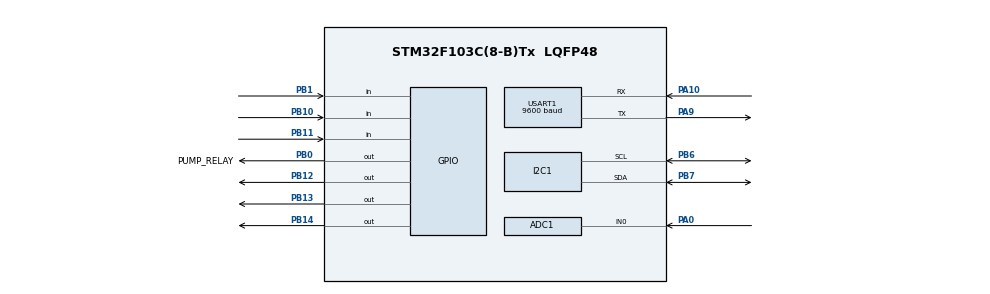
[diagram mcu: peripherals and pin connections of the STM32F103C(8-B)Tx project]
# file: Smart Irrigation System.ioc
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ADC1.Channel-0\#ChannelRegularConversion=ADC_CHANNEL_0
ADC1.NbrOfConversionFlag=1
ADC1.Rank-0\#ChannelRegularConversion=1
ADC1.SamplingTime-0\#ChannelRegularConversion=ADC_SAMPLETIME_1CYCLE_5
ADC1.master=1
FREERTOS.Events01=SoilEvent,Dynamic,NULL
FREERTOS.Mutexes01=UartMutex,Dynamic,NULL,Available;I2cMutex,Dynamic,NULL,Available
FREERTOS.Queues01=SoilAdcQueue,5,SoilData_t,0,Dynamic,NULL,NULL;SystemStatusQueue,5,SystemStatus_t,0,Dynamic,NULL,NULL;OledStatusQueue,3,SystemStatus_t,0,Dynamic,NULL,NULL
FREERTOS.Tasks01=SoilSensorTask,24,128,StartSoilSensorTask,Default,NULL,Dynamic,NULL,NULL;UartPrintTask,8,256,StartUartPrintTask,Default,NULL,Dynamic,NULL,NULL;PumpControlTask,32,512,StartPumpControlTask,Default,NULL,Dynamic,NULL,NULL;ButtonTask,24,128,StartButtonTask,Default,NULL,Dynamic,NULL,NULL;WaterTankTask,24,128,StartWaterTankTask,Default,NULL,Dynamic,NULL,NULL;SystemMonitorTa,8,128,StartSystemMonitorTask,Default,NULL,Dynamic,NULL,NULL;SystemStatusTas,8,256,StartSystemStatusTask,Default,NULL,Dynamic,NULL,NULL;OledDisplayTask,8,512,StartOledDisplayTask,Default,NULL,Dynamic,NULL,NULL
FREERTOS.configTOTAL_HEAP_SIZE=10000
FREERTOS.configUSE_NEWLIB_REENTRANT=1
Mcu.Family=STM32F1
Mcu.Name=STM32F103C(8-B)Tx
Mcu.Package=LQFP48
NVIC.PriorityGroup=NVIC_PRIORITYGROUP_4
NVIC.TIM2_IRQn=true\:15\:0\:false\:false\:true\:false\:false\:true\:true
NVIC.TimeBase=TIM2_IRQn
NVIC.TimeBaseIP=TIM2
PA0-WKUP.Signal=ADCx_IN0
PA10.Mode=Asynchronous
PA10.Signal=USART1_RX
PA13.Mode=Serial_Wire
PA13.Signal=SYS_JTMS-SWDIO
PA14.Mode=Serial_Wire
PA14.Signal=SYS_JTCK-SWCLK
PA9.Mode=Asynchronous
PA9.Signal=USART1_TX
PB0.GPIO_Label=PUMP_RELAY
PB0.Signal=GPIO_Output
PB1.GPIO_PuPd=GPIO_PULLUP
PB1.Signal=GPIO_Input
PB10.GPIO_PuPd=GPIO_PULLUP
PB10.Signal=GPIO_Input
PB11.GPIO_PuPd=GPIO_PULLUP
PB11.Signal=GPIO_Input
PB12.Signal=GPIO_Output
PB13.Signal=GPIO_Output
PB14.Signal=GPIO_Output
PB6.Mode=I2C
PB6.Signal=I2C1_SCL
PB7.Mode=I2C
PB7.Signal=I2C1_SDA
ProjectManager.HeapSize=0x200
ProjectManager.StackSize=0x400
ProjectManager.TargetToolchain=STM32CubeIDE
RCC.APB1Freq_Value=8000000
RCC.APB2Freq_Value=8000000
SH.ADCx_IN0.0=ADC1_IN0,IN0
USART1.BaudRate=9600
USART1.VirtualMode=VM_ASYNC
VP_FREERTOS_VS_CMSIS_V2.Mode=CMSIS_V2
VP_SYS_VS_tim2.Mode=TIM2
board=custom

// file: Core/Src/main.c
/* USER CODE BEGIN Header */
/**
  ******************************************************************************
  * @file           : main.c
  * @brief          : Main program body
  ******************************************************************************
  * @attention
  *
  * Copyright (c) 2026 STMicroelectronics.
  * All rights reserved.
  *
  * This software is licensed under terms that can be found in the LICENSE file
  * in the root directory of this software component.
  * If no LICENSE file comes with this software, it is provided AS-IS.
  *
  ******************************************************************************
  */
/* USER CODE END Header */
#include "main.h"
#include "cmsis_os.h"

/* USER CODE BEGIN Includes */
#include "APP.h"

/* USER CODE END Includes */

ADC_HandleTypeDef hadc1;

I2C_HandleTypeDef hi2c1;

UART_HandleTypeDef huart1;

/* Definitions for SoilSensorTask */
osThreadId_t SoilSensorTaskHandle;
const osThreadAttr_t SoilSensorTask_attributes = {
  .name = "SoilSensorTask",
  .stack_size = 128 * 4,
  .priority = (osPriority_t) osPriorityNormal,
};
/* Definitions for UartPrintTask */
osThreadId_t UartPrintTaskHandle;
const osThreadAttr_t UartPrintTask_attributes = {
  .name = "UartPrintTask",
  .stack_size = 256 * 4,
  .priority = (osPriority_t) osPriorityLow,
};
/* Definitions for PumpControlTask */
osThreadId_t PumpControlTaskHandle;
const osThreadAttr_t PumpControlTask_attributes = {
  .name = "PumpControlTask",
  .stack_size = 512 * 4,
  .priority = (osPriority_t) osPriorityAboveNormal,
};
/* Definitions for ButtonTask */
osThreadId_t ButtonTaskHandle;
const osThreadAttr_t ButtonTask_attributes = {
  .name = "ButtonTask",
  .stack_size = 128 * 4,
  .priority = (osPriority_t) osPriorityNormal,
};
/* Definitions for WaterTankTask */
osThreadId_t WaterTankTaskHandle;
const osThreadAttr_t WaterTankTask_attributes = {
  .name = "WaterTankTask",
  .stack_size = 128 * 4,
  .priority = (osPriority_t) osPriorityNormal,
};
/* Definitions for SystemMonitorTa */
osThreadId_t SystemMonitorTaHandle;
const osThreadAttr_t SystemMonitorTa_attributes = {
  .name = "SystemMonitorTa",
  .stack_size = 128 * 4,
  .priority = (osPriority_t) osPriorityLow,
};
/* Definitions for SystemStatusTas */
osThreadId_t SystemStatusTasHandle;
const osThreadAttr_t SystemStatusTas_attributes = {
  .name = "SystemStatusTas",
  .stack_size = 256 * 4,
  .priority = (osPriority_t) osPriorityLow,
};
/* Definitions for OledDisplayTask */
osThreadId_t OledDisplayTaskHandle;
const osThreadAttr_t OledDisplayTask_attributes = {
  .name = "OledDisplayTask",
  .stack_size = 512 * 4,
  .priority = (osPriority_t) osPriorityLow,
};
/* Definitions for SoilAdcQueue */
osMessageQueueId_t SoilAdcQueueHandle;
const osMessageQueueAttr_t SoilAdcQueue_attributes = {
  .name = "SoilAdcQueue"
};
/* Definitions for SystemStatusQueue */
osMessageQueueId_t SystemStatusQueueHandle;
const osMessageQueueAttr_t SystemStatusQueue_attributes = {
  .name = "SystemStatusQueue"
};
/* Definitions for OledStatusQueue */
osMessageQueueId_t OledStatusQueueHandle;
const osMessageQueueAttr_t OledStatusQueue_attributes = {
  .name = "OledStatusQueue"
};
/* Definitions for UartMutex */
osMutexId_t UartMutexHandle;
const osMutexAttr_t UartMutex_attributes = {
  .name = "UartMutex"
};
/* Definitions for I2cMutex */
osMutexId_t I2cMutexHandle;
const osMutexAttr_t I2cMutex_attributes = {
  .name = "I2cMutex"
};
/* Definitions for SoilEvent */
osEventFlagsId_t SoilEventHandle;
const osEventFlagsAttr_t SoilEvent_attributes = {
  .name = "SoilEvent"
};

void SystemClock_Config(void);
static void MX_GPIO_Init(void);
static void MX_ADC1_Init(void);
static void MX_USART1_UART_Init(void);
static void MX_I2C1_Init(void);
void StartSoilSensorTask(void *argument);
void StartUartPrintTask(void *argument);
void StartPumpControlTask(void *argument);
void StartButtonTask(void *argument);
void StartWaterTankTask(void *argument);
void StartSystemMonitorTask(void *argument);
void StartSystemStatusTask(void *argument);
void StartOledDisplayTask(void *argument);

int main(void)
{

  /* MCU Configuration--------------------------------------------------------*/

  /* Reset of all peripherals, Initializes the Flash interface and the Systick. */
  HAL_Init();

  /* Configure the system clock */
  SystemClock_Config();

  /* Initialize all configured peripherals */
  MX_GPIO_Init();
  MX_ADC1_Init();
  MX_USART1_UART_Init();
  MX_I2C1_Init();
  /* USER CODE BEGIN 2 */
  APP_Init();

  /* USER CODE END 2 */

  /* Init scheduler */
  osKernelInitialize();
  /* Create the mutex(es) */
  /* creation of UartMutex */
  UartMutexHandle = osMutexNew(&UartMutex_attributes);

  /* creation of I2cMutex */
  I2cMutexHandle = osMutexNew(&I2cMutex_attributes);

  /* Create the queue(s) */
  /* creation of SoilAdcQueue */
  SoilAdcQueueHandle = osMessageQueueNew (5, sizeof(SoilData_t), &SoilAdcQueue_attributes);

  /* creation of SystemStatusQueue */
  SystemStatusQueueHandle = osMessageQueueNew (5, sizeof(SystemStatus_t), &SystemStatusQueue_attributes);

  /* creation of OledStatusQueue */
  OledStatusQueueHandle = osMessageQueueNew (3, sizeof(SystemStatus_t), &OledStatusQueue_attributes);

  /* Create the thread(s) */
  /* creation of SoilSensorTask */
  SoilSensorTaskHandle = osThreadNew(StartSoilSensorTask, NULL, &SoilSensorTask_attributes);

  /* creation of UartPrintTask */
  UartPrintTaskHandle = osThreadNew(StartUartPrintTask, NULL, &UartPrintTask_attributes);

  /* creation of PumpControlTask */
  PumpControlTaskHandle = osThreadNew(StartPumpControlTask, NULL, &PumpControlTask_attributes);

  /* creation of ButtonTask */
  ButtonTaskHandle = osThreadNew(StartButtonTask, NULL, &ButtonTask_attributes);

  /* creation of WaterTankTask */
  WaterTankTaskHandle = osThreadNew(StartWaterTankTask, NULL, &WaterTankTask_attributes);

  /* creation of SystemMonitorTa */
  SystemMonitorTaHandle = osThreadNew(StartSystemMonitorTask, NULL, &SystemMonitorTa_attributes);

  /* creation of SystemStatusTas */
  SystemStatusTasHandle = osThreadNew(StartSystemStatusTask, NULL, &SystemStatusTas_attributes);

  /* creation of OledDisplayTask */
  OledDisplayTaskHandle = osThreadNew(StartOledDisplayTask, NULL, &OledDisplayTask_attributes);

  /* creation of SoilEvent */
  SoilEventHandle = osEventFlagsNew(&SoilEvent_attributes);

  /* Start scheduler */
  osKernelStart();

  /* We should never get here as control is now taken by the scheduler */

  /* Infinite loop */
  while (1)
  {

  }
}

void SystemClock_Config(void)
{
  RCC_OscInitTypeDef RCC_OscInitStruct = {0};
  RCC_ClkInitTypeDef RCC_ClkInitStruct = {0};
  RCC_PeriphCLKInitTypeDef PeriphClkInit = {0};

  /** Initializes the RCC Oscillators according to the specified parameters
  * in the RCC_OscInitTypeDef structure.
  */
  RCC_OscInitStruct.OscillatorType = RCC_OSCILLATORTYPE_HSI;
  RCC_OscInitStruct.HSIState = RCC_HSI_ON;
  RCC_OscInitStruct.HSICalibrationValue = RCC_HSICALIBRATION_DEFAULT;
  RCC_OscInitStruct.PLL.PLLState = RCC_PLL_NONE;
  if (HAL_RCC_OscConfig(&RCC_OscInitStruct) != HAL_OK)
  {
    Error_Handler();
  }

  /** Initializes the CPU, AHB and APB buses clocks
  */
  RCC_ClkInitStruct.ClockType = RCC_CLOCKTYPE_HCLK|RCC_CLOCKTYPE_SYSCLK
                              |RCC_CLOCKTYPE_PCLK1|RCC_CLOCKTYPE_PCLK2;
  RCC_ClkInitStruct.SYSCLKSource = RCC_SYSCLKSOURCE_HSI;
  RCC_ClkInitStruct.AHBCLKDivider = RCC_SYSCLK_DIV1;
  RCC_ClkInitStruct.APB1CLKDivider = RCC_HCLK_DIV1;
  RCC_ClkInitStruct.APB2CLKDivider = RCC_HCLK_DIV1;

  if (HAL_RCC_ClockConfig(&RCC_ClkInitStruct, FLASH_LATENCY_0) != HAL_OK)
  {
    Error_Handler();
  }
  PeriphClkInit.PeriphClockSelection = RCC_PERIPHCLK_ADC;
  PeriphClkInit.AdcClockSelection = RCC_ADCPCLK2_DIV2;
  if (HAL_RCCEx_PeriphCLKConfig(&PeriphClkInit) != HAL_OK)
  {
    Error_Handler();
  }
}

static void MX_ADC1_Init(void)
{

  ADC_ChannelConfTypeDef sConfig = {0};

  /** Common config
  */
  hadc1.Instance = ADC1;
  hadc1.Init.ScanConvMode = ADC_SCAN_DISABLE;
  hadc1.Init.ContinuousConvMode = DISABLE;
  hadc1.Init.DiscontinuousConvMode = DISABLE;
  hadc1.Init.ExternalTrigConv = ADC_SOFTWARE_START;
  hadc1.Init.DataAlign = ADC_DATAALIGN_RIGHT;
  hadc1.Init.NbrOfConversion = 1;
  if (HAL_ADC_Init(&hadc1) != HAL_OK)
  {
    Error_Handler();
  }

  /** Configure Regular Channel
  */
  sConfig.Channel = ADC_CHANNEL_0;
  sConfig.Rank = ADC_REGULAR_RANK_1;
  sConfig.SamplingTime = ADC_SAMPLETIME_1CYCLE_5;
  if (HAL_ADC_ConfigChannel(&hadc1, &sConfig) != HAL_OK)
  {
    Error_Handler();
  }

}

static void MX_I2C1_Init(void)
{

  hi2c1.Instance = I2C1;
  hi2c1.Init.ClockSpeed = 100000;
  hi2c1.Init.DutyCycle = I2C_DUTYCYCLE_2;
  hi2c1.Init.OwnAddress1 = 0;
  hi2c1.Init.AddressingMode = I2C_ADDRESSINGMODE_7BIT;
  hi2c1.Init.DualAddressMode = I2C_DUALADDRESS_DISABLE;
  hi2c1.Init.OwnAddress2 = 0;
  hi2c1.Init.GeneralCallMode = I2C_GENERALCALL_DISABLE;
  hi2c1.Init.NoStretchMode = I2C_NOSTRETCH_DISABLE;
  if (HAL_I2C_Init(&hi2c1) != HAL_OK)
  {
    Error_Handler();
  }

}

static void MX_USART1_UART_Init(void)
{

  huart1.Instance = USART1;
  huart1.Init.BaudRate = 9600;
  huart1.Init.WordLength = UART_WORDLENGTH_8B;
  huart1.Init.StopBits = UART_STOPBITS_1;
  huart1.Init.Parity = UART_PARITY_NONE;
  huart1.Init.Mode = UART_MODE_TX_RX;
  huart1.Init.HwFlowCtl = UART_HWCONTROL_NONE;
  huart1.Init.OverSampling = UART_OVERSAMPLING_16;
  if (HAL_UART_Init(&huart1) != HAL_OK)
  {
    Error_Handler();
  }

}

static void MX_GPIO_Init(void)
{
  GPIO_InitTypeDef GPIO_InitStruct = {0};

  /* GPIO Ports Clock Enable */
  __HAL_RCC_GPIOA_CLK_ENABLE();
  __HAL_RCC_GPIOB_CLK_ENABLE();

  /*Configure GPIO pin Output Level */
  HAL_GPIO_WritePin(GPIOB, PUMP_RELAY_Pin|GPIO_PIN_12|GPIO_PIN_13|GPIO_PIN_14, GPIO_PIN_RESET);

  /*Configure GPIO pins : PUMP_RELAY_Pin PB12 PB13 PB14 */
  GPIO_InitStruct.Pin = PUMP_RELAY_Pin|GPIO_PIN_12|GPIO_PIN_13|GPIO_PIN_14;
  GPIO_InitStruct.Mode = GPIO_MODE_OUTPUT_PP;
  GPIO_InitStruct.Pull = GPIO_NOPULL;
  GPIO_InitStruct.Speed = GPIO_SPEED_FREQ_LOW;
  HAL_GPIO_Init(GPIOB, &GPIO_InitStruct);

  /*Configure GPIO pins : PB1 PB10 PB11 */
  GPIO_InitStruct.Pin = GPIO_PIN_1|GPIO_PIN_10|GPIO_PIN_11;
  GPIO_InitStruct.Mode = GPIO_MODE_INPUT;
  GPIO_InitStruct.Pull = GPIO_PULLUP;
  HAL_GPIO_Init(GPIOB, &GPIO_InitStruct);

}

void StartSoilSensorTask(void *argument)
{
  /* USER CODE BEGIN 5 */
  /* Infinite loop */
	 APP_SoilSensorTask(argument);
  /* USER CODE END 5 */
}

void StartUartPrintTask(void *argument)
{
  /* USER CODE BEGIN StartUartPrintTask */
  /* Infinite loop */
	APP_UartPrintTask(argument);
  /* USER CODE END StartUartPrintTask */
}

void StartPumpControlTask(void *argument)
{
  /* USER CODE BEGIN StartPumpControlTask */
  /* Infinite loop */
	APP_PumpControlTask(argument);

  /* USER CODE END StartPumpControlTask */
}

void StartButtonTask(void *argument)
{
  /* USER CODE BEGIN StartButtonTask */
  /* Infinite loop */
	  APP_ButtonTask(argument);

  /* USER CODE END StartButtonTask */
}

void StartWaterTankTask(void *argument)
{
  /* USER CODE BEGIN StartWaterTankTask */
  /* Infinite loop */
	APP_WaterTankTask(argument);
  /* USER CODE END StartWaterTankTask */
}

void StartSystemMonitorTask(void *argument)
{
  /* USER CODE BEGIN StartSystemMonitorTask */
  /* Infinite loop */
	APP_SystemMonitorTask(argument);
  /* USER CODE END StartSystemMonitorTask */
}

void StartSystemStatusTask(void *argument)
{
  /* USER CODE BEGIN StartSystemStatusTask */
  /* Infinite loop */
	APP_SystemStatusTask(argument);
  /* USER CODE END StartSystemStatusTask */
}

void StartOledDisplayTask(void *argument)
{
  /* USER CODE BEGIN StartOledDisplayTask */
  /* Infinite loop */
	APP_OledDisplayTask(argument);
  /* USER CODE END StartOledDisplayTask */
}

void HAL_TIM_PeriodElapsedCallback(TIM_HandleTypeDef *htim)
{
  if (htim->Instance == TIM2)
  {
    HAL_IncTick();
  }
}

void Error_Handler(void)
{
  __disable_irq();
  while (1)
  {
  }
}
